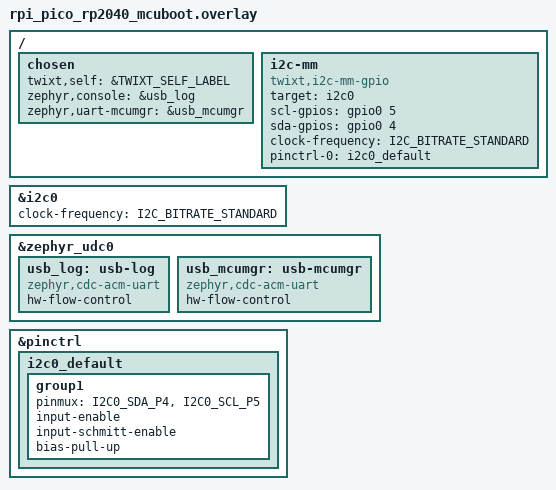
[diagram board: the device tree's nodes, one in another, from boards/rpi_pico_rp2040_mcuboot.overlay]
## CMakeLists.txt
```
# Copyright (c) 2026 Christoph Jans <jans.christoph@gmail.com>
# SPDX-License-Identifier: Apache-2.0

cmake_minimum_required(VERSION 3.20.0)

# One image per MCU: MCU picks which MCU of boards/native_sim.overlay this image is
# Under sysbuild (the Raspberry Pi Pico), -DMCU is in the sysbuild cache, not in this image's
if(SYSBUILD_CACHE)
  file(STRINGS ${SYSBUILD_CACHE} sysbuild_mcu REGEX "^MCU:")
  if(sysbuild_mcu)
    string(REGEX REPLACE "^MCU:[A-Z]*=" "" sysbuild_mcu "${sysbuild_mcu}")
    set(MCU ${sysbuild_mcu} CACHE STRING "" FORCE)
  endif()
endif()
set(MCU a CACHE STRING "MCU to build: a or b")
list(APPEND DTS_EXTRA_CPPFLAGS -DTWIXT_SELF_LABEL=mcu_${MCU})

find_package(Zephyr REQUIRED HINTS $ENV{ZEPHYR_BASE})
project(twixt_echo)

target_sources(app PRIVATE src/main.c)
target_sources_ifdef(CONFIG_USB_DEVICE_STACK_NEXT app PRIVATE src/usb.c)
```

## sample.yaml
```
# Copyright (c) 2026 Christoph Jans <jans.christoph@gmail.com>
# SPDX-License-Identifier: Apache-2.0

sample:
  name: Echo over twixt
common:
  tags:
    - i2c
tests:
  # MCU a, started by twister; pytest/test_echo.py starts b next to it
  sample.twixt.echo:
    platform_allow: native_sim
    integration_platforms:
      - native_sim
    extra_args: MCU=a
    harness: pytest
    required_applications:
      - name: sample.twixt.echo.mcu_b
  sample.twixt.echo.mcu_b:
    platform_allow: native_sim
    extra_args: MCU=b
    build_only: true
  # On real boards (README): b on an nRF7002 DK, the DUT, and a on a Raspberry
  # Pico; with --device-testing, twister flashes both and pytest/test_echo.py
  # reads both logs
  sample.twixt.echo.nrf7002dk:
    platform_allow: nrf7002dk/nrf5340/cpuapp
    integration_platforms:
      - nrf7002dk/nrf5340/cpuapp
    extra_args: MCU=b
    harness: pytest
    harness_config:
      required_devices:
        - platform: rpi_pico/rp2040/mcuboot
          application: sample.twixt.echo.rpi_pico
  # a on the Pico: the image alone, signed for the MCUboot that is on the Pico
  # (README), so that the smp runner can send it over MCUmgr
  sample.twixt.echo.rpi_pico:
    platform_allow: rpi_pico/rp2040/mcuboot
    integration_platforms:
      - rpi_pico/rp2040/mcuboot
    extra_args: MCU=a
    extra_configs:
      - CONFIG_BOOTLOADER_MCUBOOT=y
      - CONFIG_MCUBOOT_BOOTLOADER_MODE_SWAP_USING_OFFSET=y
      - CONFIG_MCUBOOT_SIGNATURE_KEY_FILE="bootloader/mcuboot/root-rsa-2048.pem"
    build_only: true
```

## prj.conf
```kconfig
# Copyright (c) 2026 Christoph Jans <jans.christoph@gmail.com>
# SPDX-License-Identifier: Apache-2.0

# CONFIG_TWIXT and the bus port come with the devicetree
CONFIG_I2C=y
CONFIG_LOG=y
CONFIG_LOG_BACKEND_SHOW_COLOR=n
```

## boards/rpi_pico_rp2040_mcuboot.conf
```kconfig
# Copyright (c) 2026 Christoph Jans <jans.christoph@gmail.com>
# SPDX-License-Identifier: Apache-2.0

# The USB device "twixt pico", brought up before main() (src/usb.c): the log on one CDC-ACM port,
# MCUmgr on another; the CDC-ACM driver must not log to itself
CONFIG_USB_DEVICE_STACK_NEXT=y
CONFIG_USBD_CDC_ACM_CLASS=y
CONFIG_CDC_ACM_SERIAL_INITIALIZE_AT_BOOT=n
CONFIG_USBD_CDC_ACM_LOG_LEVEL_OFF=y

# The ports wait for the host (hw-flow-control), also before src/usb.c brings USB up: nothing may
# print on the main thread before it, as the boot banner would. The log has a thread of its own.
CONFIG_BOOT_BANNER=n

# The DesignWare block stays the target: twixt,i2c-mm-gpio hands it its pins
CONFIG_I2C_MM_TARGET_REREGISTER=n

# The software controllers on the bus NACK their address during their own transfers, up to a
# request and a response of 64 bytes at 100 kHz
CONFIG_I2C_MM_NACK_RETRY_MS=20

# MCUmgr, to update the image over its USB port under MCUboot (smpmgr ... upgrade): img and os (reset,
# parameters)
CONFIG_MCUMGR=y
CONFIG_NET_BUF=y
CONFIG_ZCBOR=y
CONFIG_CRC=y
CONFIG_BASE64=y
CONFIG_FLASH=y
CONFIG_FLASH_MAP=y
CONFIG_STREAM_FLASH=y
CONFIG_IMG_MANAGER=y
CONFIG_IMG_ERASE_PROGRESSIVELY=y
CONFIG_MCUMGR_GRP_IMG=y
CONFIG_MCUMGR_GRP_OS=y
CONFIG_MCUMGR_GRP_OS_MCUMGR_PARAMS=y
CONFIG_REBOOT=y
CONFIG_SYSTEM_WORKQUEUE_STACK_SIZE=2048
CONFIG_UART_MCUMGR=y
CONFIG_MCUMGR_TRANSPORT_UART=y
```

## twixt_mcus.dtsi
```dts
/*
 * Copyright (c) 2026 Christoph Jans <jans.christoph@gmail.com>
 *
 * SPDX-License-Identifier: Apache-2.0
 */

/* The MCUs on the bus, the same for every image: included in the bus node of each board's
 * overlay (boards/)
 */

mcu_a: mcu-a@10 {
	compatible = "twixt,mcu";
	reg = <0x10>;
};

mcu_b: mcu-b@11 {
	compatible = "twixt,mcu";
	reg = <0x11>;
};
```

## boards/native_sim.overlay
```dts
/*
 * Copyright (c) 2026 Christoph Jans <jans.christoph@gmail.com>
 *
 * SPDX-License-Identifier: Apache-2.0
 */

/* The bus on native_sim (twixt,native-i2c-mm); TWIXT_SELF_LABEL is mcu_<MCU> */

/ {
	chosen {
		twixt,self = &TWIXT_SELF_LABEL;
	};
};

&i2c0 {
	compatible = "twixt,native-i2c-mm";
	bus-id = <5>;

#include "../twixt_mcus.dtsi"
};
```

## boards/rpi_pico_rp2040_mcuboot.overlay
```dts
/*
 * Copyright (c) 2026 Christoph Jans <jans.christoph@gmail.com>
 *
 * SPDX-License-Identifier: Apache-2.0
 */

/* On a Raspberry Pi Pico: the bus on SDA GP4 (pin 6), SCL GP5 (pin 7), at 3.3 V. I2C0 is only
 * the target, since the DesignWare block is not controller and target at once; the controller
 * is software on the same pins (twixt,i2c-mm-gpio), and pinctrl-0 gives the pins back to I2C0.
 * The Pico has two USB CDC-ACM ports: the log (if00), and MCUmgr (if02) to update the image
 * under MCUboot.
 */

#include <zephyr/dt-bindings/i2c/i2c.h>

/ {
	chosen {
		twixt,self = &TWIXT_SELF_LABEL;
		zephyr,console = &usb_log;
		zephyr,uart-mcumgr = &usb_mcumgr;
	};

	i2c-mm {
		compatible = "twixt,i2c-mm-gpio";
		target = <&i2c0>;
		scl-gpios = <&gpio0 5 0>;
		sda-gpios = <&gpio0 4 0>;
		clock-frequency = <I2C_BITRATE_STANDARD>;
		pinctrl-0 = <&i2c0_default>;
		pinctrl-names = "default";
		#address-cells = <1>;
		#size-cells = <0>;

#include "../twixt_mcus.dtsi"
	};
};

&i2c0 {
	clock-frequency = <I2C_BITRATE_STANDARD>;
};

&zephyr_udc0 {
	usb_log: usb-log {
		compatible = "zephyr,cdc-acm-uart";
		/* the log waits for the host instead of losing lines */
		hw-flow-control;
	};

	usb_mcumgr: usb-mcumgr {
		compatible = "zephyr,cdc-acm-uart";
		/* MCUmgr writes its responses with poll_out: wait instead of dropping */
		hw-flow-control;
	};
};

&pinctrl {
	i2c0_default: i2c0_default {
		group1 {
			pinmux = <I2C0_SDA_P4>, <I2C0_SCL_P5>;
			input-enable;
			input-schmitt-enable;
			bias-pull-up; /* weak; the bus needs its own pull-ups */
		};
	};
};
```

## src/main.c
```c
/*
 * Copyright (c) 2026 Christoph Jans <jans.christoph@gmail.com>
 *
 * SPDX-License-Identifier: Apache-2.0
 *
 * Echo over twixt (TWIXT_SERVICE_ECHO): two MCUs, each sends a text to the
 * other's echo service and checks that the same text comes back.
 */

#include <stdio.h>
#include <string.h>
#include <zephyr/kernel.h>
#include <zephyr/logging/log.h>

#include <twixt/twixt.h>
#include <twixt/echo.h>
#include <twixt/ping.h>

LOG_MODULE_REGISTER(echo_sample, LOG_LEVEL_INF);

#define PEER                                                                                       \
	(twixt_self_addr() == DT_REG_ADDR(DT_NODELABEL(mcu_a)) ? DT_REG_ADDR(DT_NODELABEL(mcu_b))  \
							       : DT_REG_ADDR(DT_NODELABEL(mcu_a)))

int main(void)
{
	char text[TWIXT_ECHO_MAX];
	char back[TWIXT_ECHO_MAX];
	struct twixt_ping_info info;
	int len = snprintf(text, sizeof(text), "hello from %s", twixt_self_name());
	int ret;

	/* Again and again, for a terminal opened later; the other MCU may still boot */
	for (;; k_sleep(K_SECONDS(2))) {
		ret = twixt_ping_wait(PEER, &info, K_SECONDS(5));
		if (ret == 0) {
			ret = twixt_echo(PEER, text, len, back);
		}
		if (ret) {
			LOG_ERR("0x%02x: %d", PEER, ret);
		} else if (memcmp(text, back, len) != 0) {
			LOG_ERR("echo from 0x%02x: other bytes", PEER);
		} else {
			LOG_INF("echo from 0x%02x: \"%.*s\"", PEER, len, back);
		}
	}
	return 0;
}
```
